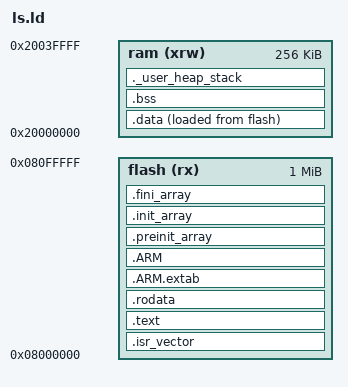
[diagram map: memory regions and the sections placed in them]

ENTRY(Reset_Handler)

_estack = 0x20040000;
_Min_Heap_Size = 0x200;
_Min_Stack_Size = 0x400;

MEMORY
{
    flash (rx)  : ORIGIN = 0x08000000, LENGTH = 1024k
    ram   (xrw) : ORIGIN = 0x20000000, LENGTH = 256k
}

SECTIONS
{
    .isr_vector :
    {
        . = ALIGN(4);
        KEEP(*(.isr_vector))
        . = ALIGN(4);
    } >flash

    .text :
    {
        . = ALIGN(4);
        *(.text*)
     
        KEEP(*(.init))
        KEEP(*(.fini))
        . = ALIGN(4);
    } > flash

    .rodata :
    {
        . = ALIGN(4);
        *(.rodata*)
        . = ALIGN(4);
    } > flash

    .ARM.extab :
    {
        *(.ARM.extab* .gnu.linkonce.armextab.*)
    } > flash

    .ARM :
    {
        __exidx_start = .;
        *(.ARM.exidx*)
        __exidx_end = .;
    } > flash

    .preinit_array :
    {
        PROVIDE_HIDDEN (__preinit_array_start = .);
        KEEP (*(.preinit_array*))
        PROVIDE_HIDDEN (__preinit_array_end = .);
    } > flash

    .init_array :
    {
        PROVIDE_HIDDEN (__init_array_start = .);
        KEEP (*(SORT(.init_array.*)))
        KEEP (*(.init_array*))
        PROVIDE_HIDDEN (__init_array_end = .);
    } > flash

    .fini_array :
    {
        PROVIDE_HIDDEN (__fini_array_start = .);
        KEEP (*(SORT(.fini_array.*)))
        KEEP(*(.fini_array*))
        PROVIDE_HIDDEN (__fini_array_end = .);
    } > flash

    _sidata = LOADADDR(.data);

    .data :
    {
        . = ALIGN(4);
        _sdata = .;
        *(.data*)
        . = ALIGN(4);
        _edata = .;
    } > ram AT > flash

    . = ALIGN(4);
    .bss :
    {
        _sbss = .;
        __bss_start = _sbss;
        *(.bss*)
        *(COMMON)
        . = ALIGN(4);
        _ebss = .;
        __bss_end__ = _ebss;
    } > ram

    ._user_heap_stack :
    {
        . = ALIGN(8);
        PROVIDE ( end = . );
        PROVIDE ( _end = . );
        . = . + _Min_Heap_Size;
        . = . + _Min_Stack_Size;
        . = ALIGN(8);
    } > ram

    /DISCARD/ :
    {
        libc.a ( * )
        libm.a ( * )
        libgcc.a ( * )
    }

    .ARM.attributes 0 :
    {
        *(.ARM.attributes)
    }
}
